# MLB0_MMR_MMRVBP register map
Vendor: Texas Instruments
Peripheral module from a debugger description file (folder J7ES).
Registers are 32-bit, read-only, reset 0x0 unless marked. A register's access mark holds for its fields unless they carry their own. Offsets are as the file gives them; lines under a group give offsets from that group; [hi:lo] are bit positions; {n}, {i} and the like mark numbered series; 'fields as' and 'values as' point back to an identical list; <NAME> marks a mode.

## MLB0_MMR_MMRVBP
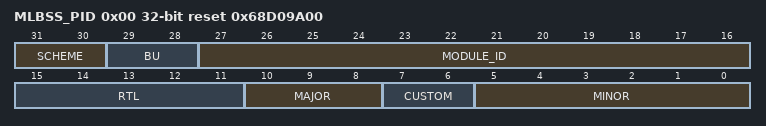
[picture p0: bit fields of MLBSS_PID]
0x00 MLBSS_PID reset 0x68D09A00 — The Revision Register contains the major and minor revisions for the module.
  [31:30] SCHEME
  [29:28] BU
  [27:16] MODULE_ID
  [15:11] RTL — RTL version
  [10:8] MAJOR — Major version
  [7:6] CUSTOM — Custom version
  [5:0] MINOR — Minor version
0x08 MLBSS_STAT — The Status register provide general status bits for the mlbss
  [1] MEM_INIT_DONE
0x0C MLBSS_DMA_CTRL rw — The DMA Control register provide control bits for the DMA Vbusp
  [2:0] PRIORITY — DMA Vbusp priority
